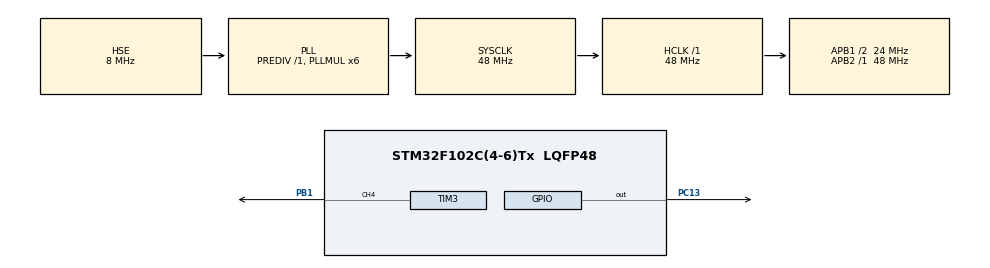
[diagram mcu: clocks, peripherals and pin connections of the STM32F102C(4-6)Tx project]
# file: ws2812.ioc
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Dma.Request0=TIM3_CH4/UP
Dma.TIM3_CH4/UP.0.Direction=DMA_MEMORY_TO_PERIPH
Dma.TIM3_CH4/UP.0.Instance=DMA1_Channel3
Dma.TIM3_CH4/UP.0.MemDataAlignment=DMA_MDATAALIGN_BYTE
Dma.TIM3_CH4/UP.0.MemInc=DMA_MINC_ENABLE
Dma.TIM3_CH4/UP.0.Mode=DMA_NORMAL
Dma.TIM3_CH4/UP.0.PeriphDataAlignment=DMA_PDATAALIGN_WORD
Dma.TIM3_CH4/UP.0.PeriphInc=DMA_PINC_DISABLE
Dma.TIM3_CH4/UP.0.Priority=DMA_PRIORITY_LOW
Mcu.Family=STM32F1
Mcu.Name=STM32F102C(4-6)Tx
Mcu.Package=LQFP48
NVIC.DMA1_Channel3_IRQn=true\:0\:0\:false\:false\:true\:false\:true\:true
NVIC.PriorityGroup=NVIC_PRIORITYGROUP_4
NVIC.TIM3_IRQn=true\:0\:0\:false\:false\:true\:true\:true\:true
PA13.Mode=Serial_Wire
PA13.Signal=SYS_JTMS-SWDIO
PA14.Mode=Serial_Wire
PA14.Signal=SYS_JTCK-SWCLK
PB1.Signal=S_TIM3_CH4
PB4.Signal=S_TIM3_CH1
PC13-TAMPER-RTC.Signal=GPIO_Output
PD0-OSC_IN.Mode=HSE-External-Oscillator
PD0-OSC_IN.Signal=RCC_OSC_IN
PD1-OSC_OUT.Mode=HSE-External-Oscillator
PD1-OSC_OUT.Signal=RCC_OSC_OUT
ProjectManager.HeapSize=0x200
ProjectManager.StackSize=0x400
ProjectManager.TargetToolchain=Makefile
RCC.AHBFreq_Value=48000000
RCC.APB1CLKDivider=RCC_HCLK_DIV2
RCC.APB1Freq_Value=24000000
RCC.APB1TimFreq_Value=48000000
RCC.APB2Freq_Value=48000000
RCC.HCLKFreq_Value=48000000
RCC.PLLMUL=RCC_PLL_MUL6
RCC.PLLSourceVirtual=RCC_PLLSOURCE_HSE
RCC.SYSCLKFreq_VALUE=48000000
RCC.SYSCLKSource=RCC_SYSCLKSOURCE_PLLCLK
RCC.USBFreq_Value=48000000
SH.S_TIM3_CH1.0=TIM3_CH1
SH.S_TIM3_CH4.0=TIM3_CH4,PWM Generation4 CH4
TIM3.Channel-PWM\ Generation4\ CH4=TIM_CHANNEL_4
TIM3.Period=59
board=custom

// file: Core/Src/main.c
/* USER CODE BEGIN Header */
/**
  ******************************************************************************
  * @file           : main.c
  * @brief          : Main program body
  ******************************************************************************
  * @attention
  *
  * Copyright (c) 2026 STMicroelectronics.
  * All rights reserved.
  *
  * This software is licensed under terms that can be found in the LICENSE file
  * in the root directory of this software component.
  * If no LICENSE file comes with this software, it is provided AS-IS.
  *
  ******************************************************************************
  */
/* USER CODE END Header */
#include "main.h"

/* USER CODE BEGIN Includes */
#include "ws2812b_config.h"
#include "ws2812b_driver.h"
#include <math.h>
/* USER CODE END Includes */

TIM_HandleTypeDef htim3;
DMA_HandleTypeDef hdma_tim3_ch4_up;

/* USER CODE BEGIN PV */
uint32_t last_blink = 0;
/* USER CODE END PV */

void SystemClock_Config(void);
static void MX_GPIO_Init(void);
static void MX_DMA_Init(void);
static void MX_TIM3_Init(void);

/* USER CODE BEGIN 0 */
void HAL_TIM_PWM_PulseFinishedCallback(TIM_HandleTypeDef *htim){
  WS2812B_Callback();
}

void Wheel(uint8_t pos, uint8_t *r, uint8_t *g, uint8_t *b)
{
    if(pos < 85) {
        *r = (85 - pos);
        *g = pos;
        *b = 0;
    }
    else if(pos < 170) {
        pos -= 85;
        *r = 0;
        *g = (85 - pos);
        *b = pos;
    }
    else {
        pos -= 170;
        *r = pos;
        *g = 0;
        *b = (85 - pos);
    }
}

/* USER CODE END 0 */

int main(void)
{

  /* MCU Configuration--------------------------------------------------------*/

  /* Reset of all peripherals, Initializes the Flash interface and the Systick. */
  HAL_Init();

  /* Configure the system clock */
  SystemClock_Config();

  /* Initialize all configured peripherals */
  MX_GPIO_Init();
  MX_DMA_Init();
  MX_TIM3_Init();
  /* USER CODE BEGIN 2 */
  WS2812B_BindTIM(&htim3, TIM_CHANNEL_4);
  WS2812B_Init();

  uint8_t hue = 0;
  float angle = 0;
  float phase_step = 1.0f;
  /* USER CODE END 2 */

  /* Infinite loop */
  /* USER CODE BEGIN WHILE */
  while (1)
  {
    for (int i = 0; i < WS2812B_NUM_LEDS; i++)
    {
        uint8_t r, g, b;

        // phase shift per LED
        float local_angle = angle + (i * phase_step);

        // sine wave (-1 to +1)
        float s = sinf(local_angle);

        // map to 0–59 PWM range
        uint8_t brightness = (uint8_t)((s + 1.0f) * 10.0f);

        // get rainbow color
        Wheel(hue + i, &r, &g, &b);

        // apply brightness scaling
        r = (r * brightness) / 59;
        g = (g * brightness) / 59;
        b = (b * brightness) / 59;

        WS2812B_SetColor(i, r, g, b);
    }

    WS2812B_Update();

    angle += 0.05f;   // wave speed
    hue++;            // rainbow drift

    HAL_Delay(10);  // controls breathing speed

    /* USER CODE END WHILE */

    /* USER CODE BEGIN 3 */
    // if(HAL_GetTick() - last_blink >= 500){
    //     last_blink = HAL_GetTick();
    //     HAL_GPIO_TogglePin(LED_INBUILT_GPIO_Port, LED_INBUILT_Pin);
    // }
  }
  /* USER CODE END 3 */
}

void SystemClock_Config(void)
{
  RCC_OscInitTypeDef RCC_OscInitStruct = {0};
  RCC_ClkInitTypeDef RCC_ClkInitStruct = {0};

  /** Initializes the RCC Oscillators according to the specified parameters
  * in the RCC_OscInitTypeDef structure.
  */
  RCC_OscInitStruct.OscillatorType = RCC_OSCILLATORTYPE_HSE;
  RCC_OscInitStruct.HSEState = RCC_HSE_ON;
  RCC_OscInitStruct.HSEPredivValue = RCC_HSE_PREDIV_DIV1;
  RCC_OscInitStruct.HSIState = RCC_HSI_ON;
  RCC_OscInitStruct.PLL.PLLState = RCC_PLL_ON;
  RCC_OscInitStruct.PLL.PLLSource = RCC_PLLSOURCE_HSE;
  RCC_OscInitStruct.PLL.PLLMUL = RCC_PLL_MUL6;
  if (HAL_RCC_OscConfig(&RCC_OscInitStruct) != HAL_OK)
  {
    Error_Handler();
  }

  /** Initializes the CPU, AHB and APB buses clocks
  */
  RCC_ClkInitStruct.ClockType = RCC_CLOCKTYPE_HCLK|RCC_CLOCKTYPE_SYSCLK
                              |RCC_CLOCKTYPE_PCLK1|RCC_CLOCKTYPE_PCLK2;
  RCC_ClkInitStruct.SYSCLKSource = RCC_SYSCLKSOURCE_PLLCLK;
  RCC_ClkInitStruct.AHBCLKDivider = RCC_SYSCLK_DIV1;
  RCC_ClkInitStruct.APB1CLKDivider = RCC_HCLK_DIV2;
  RCC_ClkInitStruct.APB2CLKDivider = RCC_HCLK_DIV1;

  if (HAL_RCC_ClockConfig(&RCC_ClkInitStruct, FLASH_LATENCY_1) != HAL_OK)
  {
    Error_Handler();
  }
}

static void MX_TIM3_Init(void)
{

  TIM_MasterConfigTypeDef sMasterConfig = {0};
  TIM_OC_InitTypeDef sConfigOC = {0};

  htim3.Instance = TIM3;
  htim3.Init.Prescaler = 0;
  htim3.Init.CounterMode = TIM_COUNTERMODE_UP;
  htim3.Init.Period = 59;
  htim3.Init.ClockDivision = TIM_CLOCKDIVISION_DIV1;
  htim3.Init.AutoReloadPreload = TIM_AUTORELOAD_PRELOAD_DISABLE;
  if (HAL_TIM_PWM_Init(&htim3) != HAL_OK)
  {
    Error_Handler();
  }
  sMasterConfig.MasterOutputTrigger = TIM_TRGO_RESET;
  sMasterConfig.MasterSlaveMode = TIM_MASTERSLAVEMODE_DISABLE;
  if (HAL_TIMEx_MasterConfigSynchronization(&htim3, &sMasterConfig) != HAL_OK)
  {
    Error_Handler();
  }
  sConfigOC.OCMode = TIM_OCMODE_PWM1;
  sConfigOC.Pulse = 0;
  sConfigOC.OCPolarity = TIM_OCPOLARITY_HIGH;
  sConfigOC.OCFastMode = TIM_OCFAST_DISABLE;
  if (HAL_TIM_PWM_ConfigChannel(&htim3, &sConfigOC, TIM_CHANNEL_4) != HAL_OK)
  {
    Error_Handler();
  }
  HAL_TIM_MspPostInit(&htim3);

}

static void MX_DMA_Init(void)
{

  /* DMA controller clock enable */
  __HAL_RCC_DMA1_CLK_ENABLE();

  /* DMA interrupt init */
  /* DMA1_Channel3_IRQn interrupt configuration */
  HAL_NVIC_SetPriority(DMA1_Channel3_IRQn, 0, 0);
  HAL_NVIC_EnableIRQ(DMA1_Channel3_IRQn);

}

static void MX_GPIO_Init(void)
{
  GPIO_InitTypeDef GPIO_InitStruct = {0};

  /* GPIO Ports Clock Enable */
  __HAL_RCC_GPIOC_CLK_ENABLE();
  __HAL_RCC_GPIOD_CLK_ENABLE();
  __HAL_RCC_GPIOB_CLK_ENABLE();
  __HAL_RCC_GPIOA_CLK_ENABLE();

  /*Configure GPIO pin Output Level */
  HAL_GPIO_WritePin(GPIOC, GPIO_PIN_13, GPIO_PIN_RESET);

  /*Configure GPIO pin : PC13 */
  GPIO_InitStruct.Pin = GPIO_PIN_13;
  GPIO_InitStruct.Mode = GPIO_MODE_OUTPUT_PP;
  GPIO_InitStruct.Pull = GPIO_NOPULL;
  GPIO_InitStruct.Speed = GPIO_SPEED_FREQ_LOW;
  HAL_GPIO_Init(GPIOC, &GPIO_InitStruct);

}

void Error_Handler(void)
{
  __disable_irq();
  while (1)
  {
  }
}
